# STM32L052 register map
File version: 1.0
CPU: CM0+ r0p0, little endian, MPU, no FPU, 4 interrupt priority bits
Registers are 32-bit, read-write, reset 0x0 unless marked. A register's access mark holds for its fields unless they carry their own. Offsets are from the block's base; lines under a group give offsets from that group; [hi:lo] are bit positions; {n}, {i} and the like mark numbered series; 'fields as' and 'values as' point back to an identical list; <NAME> marks a mode.

## Memory map
0x40000000 TIM2 size 0x400 — General-purpose-timers
0x40001000 TIM6 size 0x400 — Basic-timers
0x40002800 RTC size 0x400 — Real-time clock
0x40002C00 WWDG size 0x400 — System window watchdog
0x40003000 IWDG size 0x400 — Independent watchdog
0x40004400 USART2 size 0x400
0x40005400 I2C1 size 0x400 — Inter-integrated circuit
0x40005C00 USB_FS size 0x400 — Universal serial bus full-speed device interface
0x40006C00 CRS size 0x400 — Clock recovery system
0x40007000 PWR size 0x400 — Power control
0x40007400 DAC size 0x400 — Digital-to-analog converter
0x40007C00 LPTIM size 0x400 — Low power timer
0x40010000 SYSCFG_COMP size 0x400 — System configuration controller and Comparator
0x40010400 EXTI size 0x400 — External interrupt/event controller
0x40010800 TIM21 size 0x400 — General-purpose-timers
0x40011400 TIM22 size 0x400 — General-purpose-timers
0x40011C00 Firewall size 0x400
0x40012400 ADC size 0x400 — Analog-to-digital converter
0x40013000 SPI1 size 0x400 — Serial peripheral interface
0x40013800 USART1 size 0x400 — Universal synchronous asynchronous receiver transmitter
0x40015800 DBGMCU size 0x400 — Debug support
0x40020000 DMA1 size 0x400 — Direct memory access controller
0x40021000 RCC size 0x400 — Reset and clock control
0x40022000 Flash size 0x400
0x40023000 CRC size 0x400 — Cyclic redundancy check calculation unit
0x40024000 TSC size 0x400 — Touch sensing controller
0x40025000 RNG size 0x400 — Random number generator
0x50000000 GPIOA size 0x400 — General-purpose I/Os
0x50000400 GPIOB size 0x400 — General-purpose I/Os
0x50000800 GPIOC size 0x400
0xE000E010 STK size 0x11 — SysTick timer
0xE000E100 NVIC size 0x33D — Nested Vectored Interrupt Controller
0xE000ED00 SCB size 0x41 — System control block
0xE000ED90 MPU size 0x15 — Memory protection unit

## Interrupts
0 WWDG — Window Watchdog interrupt
1 PVD (EXTI) — PVD through EXTI line detection
2 RTC — RTC global interrupt
4 RCC — RCC global interrupt
5 EXTI0_1 (EXTI) — EXTI Line[1:0] interrupts
6 EXTI2_3 (EXTI) — EXTI Line[3:2] interrupts
7 EXTI4_15 (EXTI) — EXTI Line15 and EXTI4 interrupts
8 TSC — Touch sensing interrupt
9 DMA1_Channel1 (DMA1) — DMA1 Channel1 global interrupt
10 DMA1_Channel2_3 (DMA1) — DMA1 Channel2 and 3 interrupts
11 DMA1_Channel4_7 (DMA1) — DMA1 Channel4 to 7 interrupts
12 ADC_COMP (ADC) — ADC and comparator 1 and 2
13 LPTIM1 (LPTIM) — LPTIMER1 interrupt through EXTI29
15 TIM2 — TIM2 global interrupt
17 TIM6_DAC (TIM6) — TIM6 global interrupt and DAC
20 TIM21 — TIMER21 global interrupt
21 I2C3 (PWR) — I2C3 global interrupt
22 TIM22 — TIMER22 global interrupt
23 I2C1 — I2C1 global interrupt
25 SPI1 — SPI1_global_interrupt
27 USART1 — USART1 global interrupt
28 USART2 — USART2 global interrupt
31 USB (USB_FS) — USB event interrupt through EXTI18

## ADC — Analog-to-digital converter
Base 0x40012400
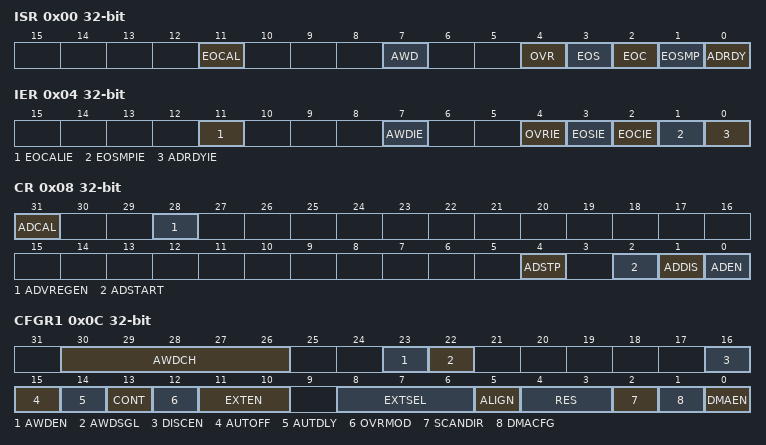
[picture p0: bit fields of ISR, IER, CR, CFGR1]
0x00 ISR — interrupt and status register
  [11] EOCAL — End Of Calibration flag
  [7] AWD — Analog watchdog flag
  [4] OVR — ADC overrun
  [3] EOS — End of sequence flag
  [2] EOC — End of conversion flag
  [1] EOSMP — End of sampling flag
  [0] ADRDY — ADC ready
0x04 IER — interrupt enable register
  [11] EOCALIE — End of calibration interrupt enable
  [7] AWDIE — Analog watchdog interrupt enable
  [4] OVRIE — Overrun interrupt enable
  [3] EOSIE — End of conversion sequence interrupt enable
  [2] EOCIE — End of conversion interrupt enable
  [1] EOSMPIE — End of sampling flag interrupt enable
  [0] ADRDYIE — ADC ready interrupt enable
0x08 CR — control register
  [31] ADCAL — ADC calibration
  [28] ADVREGEN — ADC Voltage Regulator Enable
  [4] ADSTP — ADC stop conversion command
  [2] ADSTART — ADC start conversion command
  [1] ADDIS — ADC disable command
  [0] ADEN — ADC enable command
0x0C CFGR1 — configuration register 1
  [30:26] AWDCH — Analog watchdog channel selection
  [23] AWDEN — Analog watchdog enable
  [22] AWDSGL — Enable the watchdog on a single channel or on all channels
  [16] DISCEN — Discontinuous mode
  [15] AUTOFF — Auto-off mode
  [14] AUTDLY — Auto-delayed conversion mode
  [13] CONT — Single / continuous conversion mode
  [12] OVRMOD — Overrun management mode
  [11:10] EXTEN — External trigger enable and polarity selection
  [8:6] EXTSEL — External trigger selection
  [5] ALIGN — Data alignment
  [4:3] RES — Data resolution
  [2] SCANDIR — Scan sequence direction
  [1] DMACFG — Direct memery access configuration
  [0] DMAEN — Direct memory access enable
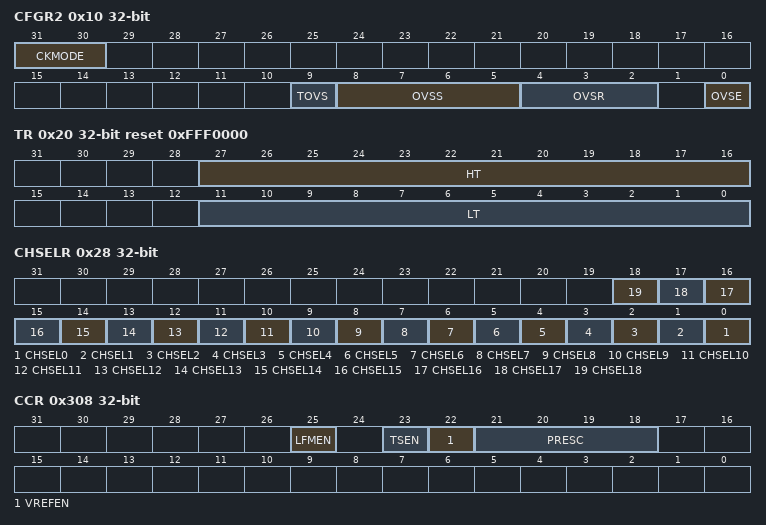
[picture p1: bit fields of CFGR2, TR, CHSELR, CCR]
0x10 CFGR2 — configuration register 2
  [31:30] CKMODE — ADC clock mode
  [9] TOVS — Triggered Oversampling
  [8:5] OVSS — Oversampling shift
  [4:2] OVSR — Oversampling ratio
  [0] OVSE — Oversampler Enable
0x14 SMPR — sampling time register
  [2:0] SMPR — Sampling time selection
0x20 TR reset 0xFFF0000 — watchdog threshold register
  [27:16] HT — Analog watchdog higher threshold
  [11:0] LT — Analog watchdog lower threshold
0x28 CHSELR — channel selection register
  [n] CHSEL{n} (n=0..18) — Channel-x selection
0x40 DR ro — data register
  [15:0] DATA — Converted data
0xB4 CALFACT — ADC Calibration factor
  [6:0] CALFACT — Calibration factor
0x308 CCR — ADC common configuration register
  [25] LFMEN — Low Frequency Mode enable
  [23] TSEN — Temperature sensor enable
  [22] VREFEN — VREFINT enable
  [21:18] PRESC — ADC prescaler
